# R7FA6T2BD register map
Vendor: Renesas Electronics Corporation; Series: RA6; File version: 1.40.00
CPU: CM33 r0p4, little endian, MPU, FPU, VTOR, 4 interrupt priority bits, 96 interrupts
Registers are 32-bit, read-write, reset 0x0 unless marked. A register's access mark holds for its fields unless they carry their own. Offsets are from the block's base; [hi:lo] are bit positions; {n}, {i} and the like mark numbered series.

## SPI_B0 — Serial Peripheral Interface 0
Base 0x4011A000
Same registers: SPI_B1 0x4011A100
0x00 SPDR — SPI Data Register
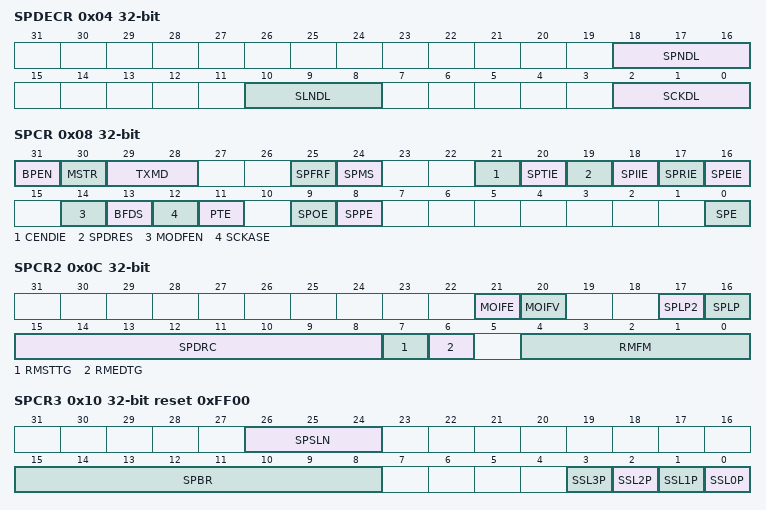
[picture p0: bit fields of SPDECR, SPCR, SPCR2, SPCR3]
0x04 SPDECR — SPI Delay Control Register
  [18:16] SPNDL — SPI Next,Access Delay
  [10:8] SLNDL — SSL Negation Delay
  [2:0] SCKDL — RSPCK Delay
0x08 SPCR — SPI Control Register
  [31] BPEN — Synchronization Circuit Bypass Enable
  [30] MSTR — SPI Master/Slave Mode Select
  [29:28] TXMD — Communication Mode Select
  [25] SPFRF — SPI Frame Format Select
  [24] SPMS — SPI Mode Select
  [21] CENDIE — SPI Communication End Interrupt Enable
  [20] SPTIE — SPI Transmit Buffer Empty Interrupt Enable
  [19] SPDRES — SPI receive data ready error select
  [18] SPIIE — SPI Idle Interrupt Enable
  [17] SPRIE — SPI Receive Buffer Full Interrupt Enable
  [16] SPEIE — SPI Error Interrupt Enable
  [14] MODFEN — Mode Fault Error Detection Enable
  [13] BFDS — Between Burst Transfer Frames Delay Select
  [12] SCKASE — RSPCK Auto,Stop Function Enable
  [11] PTE — Parity Self,Diagnosis Enable
  [9] SPOE — Parity Mode
  [8] SPPE — Parity Enable
  [0] SPE — SPI Function Enable
0x0C SPCR2 — SPI Control Register 2
  [21] MOIFE — MOSI Idle Fixed Value Enable
  [20] MOIFV — MOSI Idle Fixed Value
  [17] SPLP2 — SPI Loopback 2
  [16] SPLP — SPI Loopback
  [15:8] SPDRC — SPI received data ready detect adjustment
  [7] RMSTTG wo — Start Trigger in Master Receive only
  [6] RMEDTG wo — End Trigger in Master Receive only
  [4:0] RMFM — Frame processing count setting in Master Receive only
0x10 SPCR3 reset 0xFF00 — SPI Control Register 3
  [26:24] SPSLN — SPI Sequence Length
  [15:8] SPBR — SPI Bit Rate
  [n] SSL{n}P (n=0..3) — SSL{n} Signal Polarity
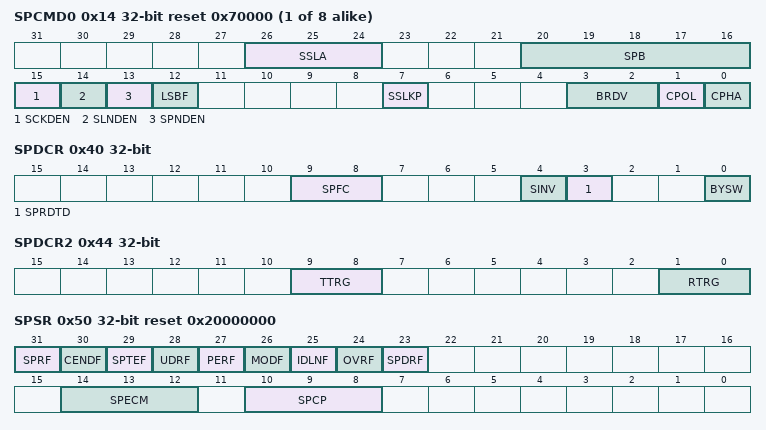
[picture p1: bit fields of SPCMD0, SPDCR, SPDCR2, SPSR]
{0x14+4i} SPCMD{i} (i=0..7) reset 0x70000 — SPI Command Register
  [26:24] SSLA — SSL Signal Assertion
  [20:16] SPB — SPI Data Length
  [15] SCKDEN — RSPCK Delay Setting Enable
  [14] SLNDEN — SSL Negation Delay Setting Enable
  [13] SPNDEN — SPI Next,Access Delay Enable
  [12] LSBF — SPI LSB First
  [7] SSLKP — SSL Signal Level Hold
  [3:2] BRDV — Bit Rate Division
  [1] CPOL — RSPCK Polarity
  [0] CPHA — RSPCK Phase
0x40 SPDCR — SPI Data Control Register
  [9:8] SPFC — Frame Count
  [4] SINV — Serial data invert bit
  [3] SPRDTD — SPI Receive Data or Transmit Data Select
  [0] BYSW — Byte Swap Operating Mode Select
0x44 SPDCR2 — SPI Data Control Register 2
  [9:8] TTRG — Transmission FIFO threshold setting
  [1:0] RTRG — Receive FIFO threshold setting
0x50 SPSR ro reset 0x20000000 — SPI Status Register
  [31] SPRF — SPI Receive Buffer Full Flag
  [30] CENDF — Communication End Flag
  [29] SPTEF — SPI Transmit Buffer Empty Flag
  [28] UDRF — Underrun Error Flag
  [27] PERF — Parity Error Flag
  [26] MODF — Mode Fault Error Flag
  [25] IDLNF — SPI Idle Flag
  [24] OVRF — Overrun Error Flag
  [23] SPDRF — SPI Receive Data Ready Flag
  [14:12] SPECM — SPI Error Command
  [10:8] SPCP — SPI Command Pointer
0x58 SPTFSR ro reset 0x4 — SPI Transfer FIFO Status Register
  [2:0] TFDN — Transmit FIFO data empty stage number
0x5C SPRFSR ro reset 0x4 — SPI Receive FIFO Status Register
  [2:0] RFDN — Receive FIFO data store stage number
0x60 SPPSR ro — SPI Polling Register
  [0] SPEPS — SPI Polling Status
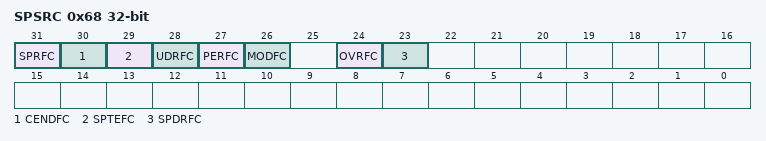
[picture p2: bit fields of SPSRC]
0x68 SPSRC — SPI Status Clear Register
  [31] SPRFC wo — SPI Receive Buffer Full Flag Clear
  [30] CENDFC wo — Communication End Flag Clear
  [29] SPTEFC wo — SPI Transmit Buffer Empty Flag Clear
  [28] UDRFC wo — Underrun Error Flag Clear
  [27] PERFC wo — Parity Error Flag Clear
  [26] MODFC wo — Mode Fault Error Flag Clear
  [24] OVRFC wo — Overrun Error Flag Clear
  [23] SPDRFC wo — SPI Receive Data Ready Flag Clear
0x6C SPFCR — SPI FIFO Clear Register
  [0] SPFRST wo — SPI FIFO clear
